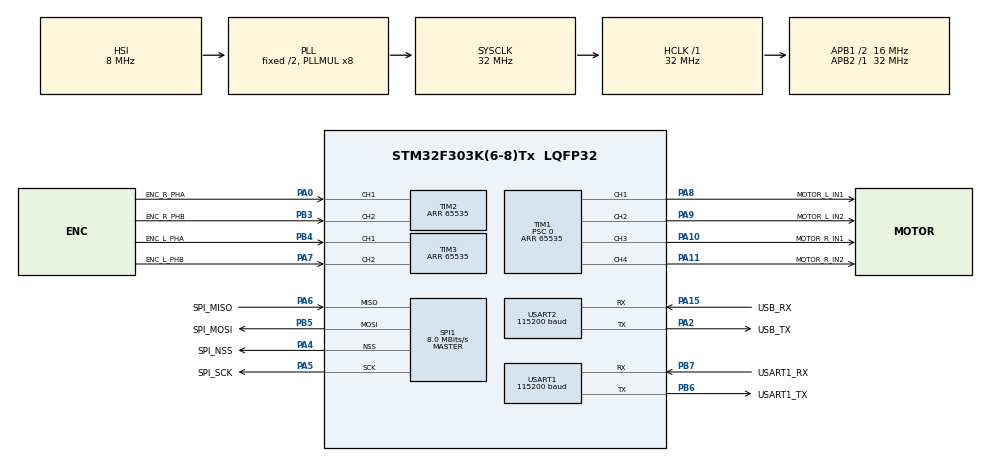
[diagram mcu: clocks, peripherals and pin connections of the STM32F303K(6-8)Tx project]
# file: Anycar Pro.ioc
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FREERTOS.HEAP_NUMBER=5
FREERTOS.Queues01=receivedBytesQueue,32,1,1,Dynamic,NULL,NULL;transmitMessagesQueue,8,32,1,Dynamic,NULL,NULL;heartbeatsQueue,4,8,1,Dynamic,NULL,NULL;commandsQueue,4,16,1,Dynamic,NULL,NULL
FREERTOS.Tasks01=defaultTask,8,128,StartDefaultTask,As weak,NULL,Dynamic,NULL,NULL;transmitMessagesTask,8,160,StartTransmitMessagesTask,As external,NULL,Dynamic,NULL,NULL;parseMessagesTask,8,96,StartParseMessagesTask,As external,NULL,Dynamic,NULL,NULL;executeCommandsTask,8,96,StartExecuteCommandsTask,As external,NULL,Dynamic,NULL,NULL;checkConnectionTask,8,96,StartCheckConnectionTask,As external,NULL,Dynamic,NULL,NULL
FREERTOS.Timers01=sendHeartbeatsTimer,SendHeartbeatsCallback,osTimerPeriodic,As external,NULL,Dynamic,NULL;reportStatusTimer,ReportStatusCallback,osTimerPeriodic,As external,NULL,Dynamic,NULL
FREERTOS.configMAX_TASK_NAME_LEN=32
FREERTOS.configMINIMAL_STACK_SIZE=64
FREERTOS.configTOTAL_HEAP_SIZE=4096
FREERTOS.configUSE_NEWLIB_REENTRANT=0
Mcu.Family=STM32F3
Mcu.Name=STM32F303K(6-8)Tx
Mcu.Package=LQFP32
NVIC.PriorityGroup=NVIC_PRIORITYGROUP_4
NVIC.TIM6_DAC1_IRQn=true\:5\:0\:false\:false\:true\:true\:true\:true\:true
NVIC.TIM7_DAC2_IRQn=true\:15\:0\:false\:false\:true\:false\:false\:true\:true
NVIC.TimeBase=TIM7_DAC2_IRQn
NVIC.TimeBaseIP=TIM7
NVIC.USART1_IRQn=true\:5\:0\:false\:false\:true\:true\:true\:true\:true
NVIC.USART2_IRQn=true\:5\:0\:false\:false\:true\:true\:true\:true\:true
PA0.GPIO_Label=ENC_R_PHA
PA0.GPIO_PuPd=GPIO_PULLDOWN
PA0.Signal=S_TIM2_CH1_ETR
PA10.GPIO_Label=MOTOR_R_IN1
PA10.Signal=S_TIM1_CH3
PA11.GPIO_Label=MOTOR_R_IN2
PA11.Signal=S_TIM1_CH4
PA13.GPIO_Label=SWDIO
PA13.Mode=Serial_Wire
PA13.Signal=SYS_JTMS-SWDIO
PA14.GPIO_Label=SWCLK
PA14.Mode=Serial_Wire
PA14.Signal=SYS_JTCK-SWCLK
PA15.GPIO_Label=USB_RX
PA15.Mode=Asynchronous
PA15.Signal=USART2_RX
PA2.GPIO_Label=USB_TX
PA2.Mode=Asynchronous
PA2.Signal=USART2_TX
PA4.GPIO_Label=SPI_NSS
PA4.Mode=NSS_Signal_Hard_Output
PA4.Signal=SPI1_NSS
PA5.GPIO_Label=SPI_SCK
PA5.Mode=Full_Duplex_Master
PA5.Signal=SPI1_SCK
PA6.GPIO_Label=SPI_MISO
PA6.Mode=Full_Duplex_Master
PA6.Signal=SPI1_MISO
PA7.GPIO_Label=ENC_L_PHB
PA7.GPIO_PuPd=GPIO_PULLDOWN
PA7.Signal=S_TIM3_CH2
PA8.GPIO_Label=MOTOR_L_IN1
PA8.Signal=S_TIM1_CH1
PA9.GPIO_Label=MOTOR_L_IN2
PA9.Signal=S_TIM1_CH2
PB3.GPIO_Label=ENC_R_PHB
PB3.GPIO_PuPd=GPIO_PULLDOWN
PB3.Signal=S_TIM2_CH2
PB4.GPIO_Label=ENC_L_PHA
PB4.GPIO_PuPd=GPIO_PULLDOWN
PB4.Signal=S_TIM3_CH1
PB5.GPIO_Label=SPI_MOSI
PB5.Mode=Full_Duplex_Master
PB5.Signal=SPI1_MOSI
PB6.GPIO_Label=USART1_TX
PB6.Mode=Asynchronous
PB6.Signal=USART1_TX
PB7.GPIO_Label=USART1_RX
PB7.Mode=Asynchronous
PB7.Signal=USART1_RX
PF0\ /\ OSC_IN.GPIO_Label=MCO
PF0\ /\ OSC_IN.Signal=RCC_OSC_IN
ProjectManager.HeapSize=0x200
ProjectManager.StackSize=0x400
ProjectManager.TargetToolchain=Makefile
RCC.AHBFreq_Value=32000000
RCC.APB1CLKDivider=RCC_HCLK_DIV2
RCC.APB1Freq_Value=16000000
RCC.APB1TimFreq_Value=32000000
RCC.APB2Freq_Value=32000000
RCC.APB2TimFreq_Value=32000000
RCC.CortexFreq_Value=32000000
RCC.HCLKFreq_Value=32000000
RCC.HSE_VALUE=8000000
RCC.HSI_VALUE=8000000
RCC.PLLMUL=RCC_PLL_MUL8
RCC.SYSCLKFreq_VALUE=32000000
RCC.SYSCLKSourceVirtual=RCC_SYSCLKSOURCE_PLLCLK
SH.S_TIM1_CH1.0=TIM1_CH1,PWM Generation1 CH1
SH.S_TIM1_CH2.0=TIM1_CH2,PWM Generation2 CH2
SH.S_TIM1_CH3.0=TIM1_CH3,PWM Generation3 CH3
SH.S_TIM1_CH4.0=TIM1_CH4,PWM Generation4 CH4
SH.S_TIM2_CH1_ETR.0=TIM2_CH1,Encoder_Interface
SH.S_TIM2_CH2.0=TIM2_CH2,Encoder_Interface
SH.S_TIM3_CH1.0=TIM3_CH1,Encoder_Interface
SH.S_TIM3_CH2.0=TIM3_CH2,Encoder_Interface
SPI1.BaudRatePrescaler=SPI_BAUDRATEPRESCALER_4
SPI1.CalculateBaudRate=8.0 MBits/s
SPI1.Direction=SPI_DIRECTION_2LINES
SPI1.Mode=SPI_MODE_MASTER
SPI1.NSSPMode=SPI_NSS_PULSE_ENABLE
SPI1.VirtualNSS=VM_NSSHARD
SPI1.VirtualType=VM_MASTER
TIM1.Channel-PWM\ Generation1\ CH1=TIM_CHANNEL_1
TIM1.Channel-PWM\ Generation2\ CH2=TIM_CHANNEL_2
TIM1.Channel-PWM\ Generation3\ CH3=TIM_CHANNEL_3
TIM1.Channel-PWM\ Generation4\ CH4=TIM_CHANNEL_4
TIM1.Period=65535
TIM1.Prescaler=0
TIM2.EncoderMode=TIM_ENCODERMODE_TI12
TIM2.IC1Filter=1
TIM2.IC2Filter=1
TIM2.Period=65535
TIM3.EncoderMode=TIM_ENCODERMODE_TI12
TIM3.IC1Filter=1
TIM3.IC1Polarity=TIM_ICPOLARITY_RISING
TIM3.IC2Filter=1
TIM3.IC2Polarity=TIM_ICPOLARITY_RISING
TIM3.Period=65535
TIM6.Period=10000-1
TIM6.Prescaler=32-1
USART1.BaudRate=115200
USART1.VirtualMode-Asynchronous=VM_ASYNC
USART2.BaudRate=115200
USART2.VirtualMode-Asynchronous=VM_ASYNC
VP_FREERTOS_VS_CMSIS_V2.Mode=CMSIS_V2
VP_SYS_VS_tim7.Mode=TIM7
VP_TIM1_VS_ClockSourceINT.Mode=Internal
VP_TIM6_VS_ClockSourceINT.Mode=Enable_Timer
board=NUCLEO-F303K8

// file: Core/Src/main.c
/* USER CODE BEGIN Header */
/**
  ******************************************************************************
  * @file           : main.c
  * @brief          : Main program body
  ******************************************************************************
  * @attention
  *
  * Copyright (c) 2022 STMicroelectronics.
  * All rights reserved.
  *
  * This software is licensed under terms that can be found in the LICENSE file
  * in the root directory of this software component.
  * If no LICENSE file comes with this software, it is provided AS-IS.
  *
  ******************************************************************************
  */
/* USER CODE END Header */
#include "main.h"
#include "cmsis_os.h"
#include "spi.h"
#include "tim.h"
#include "usart.h"
#include "gpio.h"

/* USER CODE BEGIN PV */
extern TIM_HandleTypeDef htim7;
__attribute__((section(".ccmram"))) uint8_t ucHeap[configTOTAL_HEAP_SIZE];
/* USER CODE END PV */

void SystemClock_Config(void);
void MX_FREERTOS_Init(void);
/* USER CODE BEGIN PFP */
void HAL_SysTimerCallback(TIM_HandleTypeDef *htim);
/* USER CODE END PFP */

int main(void)
{

  /* MCU Configuration--------------------------------------------------------*/

  /* Reset of all peripherals, Initializes the Flash interface and the Systick. */
  HAL_Init();

  /* Configure the system clock */
  SystemClock_Config();

  /* Initialize all configured peripherals */
  MX_GPIO_Init();
  MX_SPI1_Init();
  MX_TIM1_Init();
  MX_TIM2_Init();
  MX_TIM3_Init();
  MX_USART1_UART_Init();
  MX_USART2_UART_Init();
  MX_TIM6_Init();
  /* USER CODE BEGIN 2 */
  htim7.PeriodElapsedCallback = HAL_SysTimerCallback;
  /* USER CODE END 2 */

  /* Init scheduler */
  osKernelInitialize();  /* Call init function for freertos objects (in freertos.c) */
  MX_FREERTOS_Init();

  /* Start scheduler */
  osKernelStart();

  /* We should never get here as control is now taken by the scheduler */
  /* Infinite loop */
  while (1)
  {

  }
}

void SystemClock_Config(void)
{
  RCC_OscInitTypeDef RCC_OscInitStruct = {0};
  RCC_ClkInitTypeDef RCC_ClkInitStruct = {0};
  RCC_PeriphCLKInitTypeDef PeriphClkInit = {0};

  /** Initializes the RCC Oscillators according to the specified parameters
  * in the RCC_OscInitTypeDef structure.
  */
  RCC_OscInitStruct.OscillatorType = RCC_OSCILLATORTYPE_HSI;
  RCC_OscInitStruct.HSIState = RCC_HSI_ON;
  RCC_OscInitStruct.HSICalibrationValue = RCC_HSICALIBRATION_DEFAULT;
  RCC_OscInitStruct.PLL.PLLState = RCC_PLL_ON;
  RCC_OscInitStruct.PLL.PLLSource = RCC_PLLSOURCE_HSI;
  RCC_OscInitStruct.PLL.PLLMUL = RCC_PLL_MUL8;
  if (HAL_RCC_OscConfig(&RCC_OscInitStruct) != HAL_OK)
  {
    Error_Handler();
  }

  /** Initializes the CPU, AHB and APB buses clocks
  */
  RCC_ClkInitStruct.ClockType = RCC_CLOCKTYPE_HCLK|RCC_CLOCKTYPE_SYSCLK
                              |RCC_CLOCKTYPE_PCLK1|RCC_CLOCKTYPE_PCLK2;
  RCC_ClkInitStruct.SYSCLKSource = RCC_SYSCLKSOURCE_PLLCLK;
  RCC_ClkInitStruct.AHBCLKDivider = RCC_SYSCLK_DIV1;
  RCC_ClkInitStruct.APB1CLKDivider = RCC_HCLK_DIV2;
  RCC_ClkInitStruct.APB2CLKDivider = RCC_HCLK_DIV1;

  if (HAL_RCC_ClockConfig(&RCC_ClkInitStruct, FLASH_LATENCY_1) != HAL_OK)
  {
    Error_Handler();
  }
  PeriphClkInit.PeriphClockSelection = RCC_PERIPHCLK_USART1|RCC_PERIPHCLK_TIM1;
  PeriphClkInit.Usart1ClockSelection = RCC_USART1CLKSOURCE_PCLK1;
  PeriphClkInit.Tim1ClockSelection = RCC_TIM1CLK_HCLK;
  if (HAL_RCCEx_PeriphCLKConfig(&PeriphClkInit) != HAL_OK)
  {
    Error_Handler();
  }
}

/* USER CODE BEGIN 4 */
void HAL_SysTimerCallback(TIM_HandleTypeDef *htim)
{
  UNUSED(htim);
  HAL_IncTick();
}
/* USER CODE END 4 */

void HAL_TIM_PeriodElapsedCallback(TIM_HandleTypeDef *htim)
{
  if (htim->Instance == TIM7) {
    HAL_IncTick();
  }
}

void Error_Handler(void)
{
  __disable_irq();
  while (1)
  {
  }
}

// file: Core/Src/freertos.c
/* USER CODE BEGIN Header */
/**
  ******************************************************************************
  * File Name          : freertos.c
  * Description        : Code for freertos applications
  ******************************************************************************
  * @attention
  *
  * Copyright (c) 2022 STMicroelectronics.
  * All rights reserved.
  *
  * This software is licensed under terms that can be found in the LICENSE file
  * in the root directory of this software component.
  * If no LICENSE file comes with this software, it is provided AS-IS.
  *
  ******************************************************************************
  */
/* USER CODE END Header */

#include "FreeRTOS.h"
#include "task.h"
#include "main.h"
#include "cmsis_os.h"

/* Definitions for defaultTask */
osThreadId_t defaultTaskHandle;
const osThreadAttr_t defaultTask_attributes = {
  .name = "defaultTask",
  .stack_size = 128 * 4,
  .priority = (osPriority_t) osPriorityLow,
};
/* Definitions for transmitMessagesTask */
osThreadId_t transmitMessagesTaskHandle;
const osThreadAttr_t transmitMessagesTask_attributes = {
  .name = "transmitMessagesTask",
  .stack_size = 160 * 4,
  .priority = (osPriority_t) osPriorityLow,
};
/* Definitions for parseMessagesTask */
osThreadId_t parseMessagesTaskHandle;
const osThreadAttr_t parseMessagesTask_attributes = {
  .name = "parseMessagesTask",
  .stack_size = 96 * 4,
  .priority = (osPriority_t) osPriorityLow,
};
/* Definitions for executeCommandsTask */
osThreadId_t executeCommandsTaskHandle;
const osThreadAttr_t executeCommandsTask_attributes = {
  .name = "executeCommandsTask",
  .stack_size = 96 * 4,
  .priority = (osPriority_t) osPriorityLow,
};
/* Definitions for checkConnectionTask */
osThreadId_t checkConnectionTaskHandle;
const osThreadAttr_t checkConnectionTask_attributes = {
  .name = "checkConnectionTask",
  .stack_size = 96 * 4,
  .priority = (osPriority_t) osPriorityLow,
};
/* Definitions for receivedBytesQueue */
osMessageQueueId_t receivedBytesQueueHandle;
const osMessageQueueAttr_t receivedBytesQueue_attributes = {
  .name = "receivedBytesQueue"
};
/* Definitions for transmitMessagesQueue */
osMessageQueueId_t transmitMessagesQueueHandle;
const osMessageQueueAttr_t transmitMessagesQueue_attributes = {
  .name = "transmitMessagesQueue"
};
/* Definitions for heartbeatsQueue */
osMessageQueueId_t heartbeatsQueueHandle;
const osMessageQueueAttr_t heartbeatsQueue_attributes = {
  .name = "heartbeatsQueue"
};
/* Definitions for commandsQueue */
osMessageQueueId_t commandsQueueHandle;
const osMessageQueueAttr_t commandsQueue_attributes = {
  .name = "commandsQueue"
};
/* Definitions for sendHeartbeatsTimer */
osTimerId_t sendHeartbeatsTimerHandle;
const osTimerAttr_t sendHeartbeatsTimer_attributes = {
  .name = "sendHeartbeatsTimer"
};
/* Definitions for reportStatusTimer */
osTimerId_t reportStatusTimerHandle;
const osTimerAttr_t reportStatusTimer_attributes = {
  .name = "reportStatusTimer"
};

void StartDefaultTask(void *argument);
extern void StartTransmitMessagesTask(void *argument);
extern void StartParseMessagesTask(void *argument);
extern void StartExecuteCommandsTask(void *argument);
extern void StartCheckConnectionTask(void *argument);
extern void SendHeartbeatsCallback(void *argument);
extern void ReportStatusCallback(void *argument);

void MX_FREERTOS_Init(void); /* (MISRA C 2004 rule 8.1) */

void MX_FREERTOS_Init(void) {

  /* Create the timer(s) */
  /* creation of sendHeartbeatsTimer */
  sendHeartbeatsTimerHandle = osTimerNew(SendHeartbeatsCallback, osTimerPeriodic, NULL, &sendHeartbeatsTimer_attributes);

  /* creation of reportStatusTimer */
  reportStatusTimerHandle = osTimerNew(ReportStatusCallback, osTimerPeriodic, NULL, &reportStatusTimer_attributes);

  /* Create the queue(s) */
  /* creation of receivedBytesQueue */
  receivedBytesQueueHandle = osMessageQueueNew (32, 1, &receivedBytesQueue_attributes);

  /* creation of transmitMessagesQueue */
  transmitMessagesQueueHandle = osMessageQueueNew (8, 32, &transmitMessagesQueue_attributes);

  /* creation of heartbeatsQueue */
  heartbeatsQueueHandle = osMessageQueueNew (4, 8, &heartbeatsQueue_attributes);

  /* creation of commandsQueue */
  commandsQueueHandle = osMessageQueueNew (4, 16, &commandsQueue_attributes);

  /* Create the thread(s) */
  /* creation of defaultTask */
  defaultTaskHandle = osThreadNew(StartDefaultTask, NULL, &defaultTask_attributes);

  /* creation of transmitMessagesTask */
  transmitMessagesTaskHandle = osThreadNew(StartTransmitMessagesTask, NULL, &transmitMessagesTask_attributes);

  /* creation of parseMessagesTask */
  parseMessagesTaskHandle = osThreadNew(StartParseMessagesTask, NULL, &parseMessagesTask_attributes);

  /* creation of executeCommandsTask */
  executeCommandsTaskHandle = osThreadNew(StartExecuteCommandsTask, NULL, &executeCommandsTask_attributes);

  /* creation of checkConnectionTask */
  checkConnectionTaskHandle = osThreadNew(StartCheckConnectionTask, NULL, &checkConnectionTask_attributes);

}

__weak void StartDefaultTask(void *argument)
{
  for(;;)
  {
    osDelay(1);
  }
}
